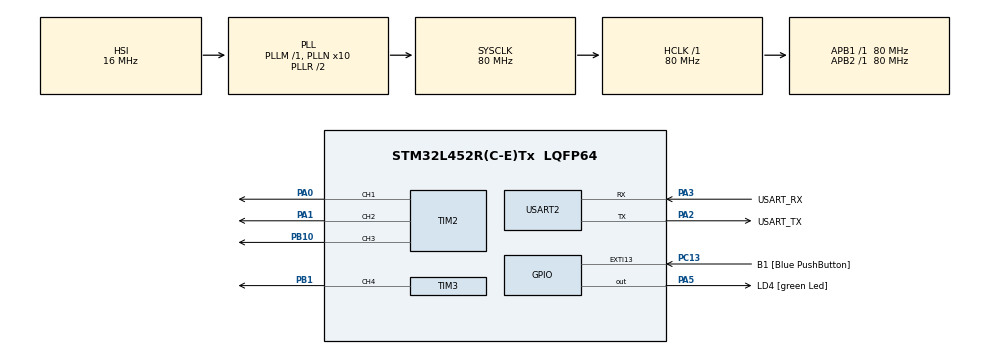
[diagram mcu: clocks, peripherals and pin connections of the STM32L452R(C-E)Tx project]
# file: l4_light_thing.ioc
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Mcu.Family=STM32L4
PA2.GPIO_PuPd=GPIO_NOPULL
RCC.CortexFreq_Value=80000000
PH0-OSC_IN\ (PH0).Signal=RCC_OSC_IN
Dma.TIM3_CH4/UP.0.Mode=DMA_NORMAL
PA3.GPIO_PuPd=GPIO_NOPULL
PA2.GPIO_Speed=GPIO_SPEED_FREQ_VERY_HIGH
PC15-OSC32_OUT\ (PC15).Mode=LSE-External-Oscillator
TIM2.Channel-PWM\ Generation2\ CH2=TIM_CHANNEL_2
PC13.GPIO_Label=B1 [Blue PushButton]
PA3.GPIO_Speed=GPIO_SPEED_FREQ_VERY_HIGH
TIM3.Channel-PWM\ Generation4\ CH4=TIM_CHANNEL_4
RCC.SYSCLKSource=RCC_SYSCLKSOURCE_PLLCLK
ProjectManager.StackSize=0x400
PC14-OSC32_IN\ (PC14).Mode=LSE-External-Oscillator
NVIC.DMA1_Channel3_IRQn=true\:0\:0\:false\:false\:true\:false\:true
PA14\ (JTCK/SWCLK).Signal=SYS_JTCK-SWCLK
RCC.HCLKFreq_Value=80000000
RCC.APB2TimFreq_Value=80000000
RCC.AHBFreq_Value=80000000
RCC.PREFETCH_ENABLE=1
RCC.HSE_VALUE=8000000
USART2.VirtualMode-Asynchronous=VM_ASYNC
PA13\ (JTMS/SWDIO).GPIO_Label=TMS
PB1.GPIO_Speed=GPIO_SPEED_FREQ_VERY_HIGH
PA5.GPIO_PuPd=GPIO_NOPULL
PC13.GPIO_PuPd=GPIO_NOPULL
PA14\ (JTCK/SWCLK).Mode=Serial_Wire
TIM2.Channel-PWM\ Generation1\ CH1=TIM_CHANNEL_1
PA0.Signal=S_TIM2_CH1
Mcu.Package=LQFP64
PB1.Signal=S_TIM3_CH4
Dma.TIM3_CH4/UP.0.Priority=DMA_PRIORITY_LOW
PA2.GPIO_Label=USART_TX
Dma.TIM3_CH4/UP.0.Direction=DMA_MEMORY_TO_PERIPH
PA14\ (JTCK/SWCLK).GPIO_Label=TCK
RCC.APB1TimFreq_Value=80000000
Dma.Request0=TIM3_CH4/UP
Dma.TIM3_CH4/UP.0.PeriphDataAlignment=DMA_PDATAALIGN_WORD
VP_TIM3_VS_ClockSourceINT.Mode=Internal
RCC.HSI48_VALUE=48000000
PA3.Signal=USART2_RX
PA2.GPIO_Mode=GPIO_MODE_AF_PP
PB3\ (JTDO/TRACESWO).GPIO_Label=SWO
RCC.MSI_VALUE=4000000
RCC.PLLSourceVirtual=RCC_PLLSOURCE_HSI
SH.S_TIM2_CH1.0=TIM2_CH1,PWM Generation1 CH1
PA13\ (JTMS/SWDIO).Mode=Serial_Wire
TIM3.AutoReloadPreload=TIM_AUTORELOAD_PRELOAD_ENABLE
PC13.Signal=GPXTI13
PC15-OSC32_OUT\ (PC15).Signal=RCC_OSC32_OUT
PH1-OSC_OUT\ (PH1).Signal=RCC_OSC_OUT
PA3.Mode=Asynchronous
SH.S_TIM2_CH2.0=TIM2_CH2,PWM Generation2 CH2
PB3\ (JTDO/TRACESWO).Signal=SYS_JTDO-SWO
ProjectManager.TargetToolchain=Makefile
PA3.GPIO_Mode=GPIO_MODE_AF_PP
Dma.TIM3_CH4/UP.0.Instance=DMA1_Channel3
RCC.USBFreq_Value=64000000
PA1.Signal=S_TIM2_CH2
PB10.Signal=S_TIM2_CH3
PA5.Signal=GPIO_Output
board=NUCLEO-L452RE
RCC.VCOOutputFreq_Value=160000000
RCC.APB2Freq_Value=80000000
PA5.GPIO_ModeDefaultOutputPP=GPIO_MODE_OUTPUT_PP
SH.S_TIM2_CH3.0=TIM2_CH3,PWM Generation3 CH3
RCC.ADCFreq_Value=64000000
TIM2.Channel-PWM\ Generation3\ CH3=TIM_CHANNEL_3
Dma.TIM3_CH4/UP.0.MemInc=DMA_MINC_ENABLE
Mcu.Name=STM32L452R(C-E)Tx
PA2.Signal=USART2_TX
RCC.SYSCLKFreq_VALUE=80000000
PA5.GPIO_Label=LD4 [green Led]
PC13.GPIO_ModeDefaultEXTI=GPIO_MODE_IT_FALLING
PC14-OSC32_IN\ (PC14).Signal=RCC_OSC32_IN
ProjectManager.HeapSize=0x200
Dma.TIM3_CH4/UP.0.MemDataAlignment=DMA_MDATAALIGN_BYTE
RCC.HSI_VALUE=16000000
PA5.GPIO_Speed=GPIO_SPEED_FREQ_LOW
NVIC.PriorityGroup=NVIC_PRIORITYGROUP_4
RCC.PLLN=10
PA2.Mode=Asynchronous
RCC.APB1Freq_Value=80000000
Dma.TIM3_CH4/UP.0.PeriphInc=DMA_PINC_DISABLE
PA13\ (JTMS/SWDIO).Signal=SYS_JTMS-SWDIO
PA3.GPIO_Label=USART_RX
SH.S_TIM3_CH4.0=TIM3_CH4,PWM Generation4 CH4

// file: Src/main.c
/* USER CODE BEGIN Header */
/**
  ******************************************************************************
  * @file           : main.c
  * @brief          : Main program body
  ******************************************************************************
  * @attention
  *
  * <h2><center>&copy; Copyright (c) 2020 STMicroelectronics.
  * All rights reserved.</center></h2>
  *
  * This software component is licensed by ST under BSD 3-Clause license,
  * the "License"; You may not use this file except in compliance with the
  * License. You may obtain a copy of the License at:
  *                        opensource.org/licenses/BSD-3-Clause
  *
  ******************************************************************************
  */
/* USER CODE END Header */

#include "main.h"
#include "dma.h"
#include "tim.h"
#include "usart.h"
#include "gpio.h"

/* USER CODE BEGIN Includes */
#include "addressable_led_driver.h"
/* USER CODE END Includes */

void SystemClock_Config(void);

int main(void)
{

  /* MCU Configuration--------------------------------------------------------*/

  /* Reset of all peripherals, Initializes the Flash interface and the Systick. */
  HAL_Init();

  /* Configure the system clock */
  SystemClock_Config();

  /* Initialize all configured peripherals */
  MX_GPIO_Init();
  MX_DMA_Init();
  MX_TIM2_Init();
  MX_TIM3_Init();
  MX_USART2_UART_Init();
  /* USER CODE BEGIN 2 */
  AddrLED_Init();
  /* USER CODE END 2 */

  /* Infinite loop */
  while (1)
  {

  }
}

void SystemClock_Config(void)
{
  RCC_OscInitTypeDef RCC_OscInitStruct = {0};
  RCC_ClkInitTypeDef RCC_ClkInitStruct = {0};
  RCC_PeriphCLKInitTypeDef PeriphClkInit = {0};

  /** Initializes the CPU, AHB and APB busses clocks
  */
  RCC_OscInitStruct.OscillatorType = RCC_OSCILLATORTYPE_HSI;
  RCC_OscInitStruct.HSIState = RCC_HSI_ON;
  RCC_OscInitStruct.HSICalibrationValue = RCC_HSICALIBRATION_DEFAULT;
  RCC_OscInitStruct.PLL.PLLState = RCC_PLL_ON;
  RCC_OscInitStruct.PLL.PLLSource = RCC_PLLSOURCE_HSI;
  RCC_OscInitStruct.PLL.PLLM = 1;
  RCC_OscInitStruct.PLL.PLLN = 10;
  RCC_OscInitStruct.PLL.PLLP = RCC_PLLP_DIV7;
  RCC_OscInitStruct.PLL.PLLQ = RCC_PLLQ_DIV2;
  RCC_OscInitStruct.PLL.PLLR = RCC_PLLR_DIV2;
  if (HAL_RCC_OscConfig(&RCC_OscInitStruct) != HAL_OK)
  {
    Error_Handler();
  }
  /** Initializes the CPU, AHB and APB busses clocks
  */
  RCC_ClkInitStruct.ClockType = RCC_CLOCKTYPE_HCLK|RCC_CLOCKTYPE_SYSCLK
                              |RCC_CLOCKTYPE_PCLK1|RCC_CLOCKTYPE_PCLK2;
  RCC_ClkInitStruct.SYSCLKSource = RCC_SYSCLKSOURCE_PLLCLK;
  RCC_ClkInitStruct.AHBCLKDivider = RCC_SYSCLK_DIV1;
  RCC_ClkInitStruct.APB1CLKDivider = RCC_HCLK_DIV1;
  RCC_ClkInitStruct.APB2CLKDivider = RCC_HCLK_DIV1;

  if (HAL_RCC_ClockConfig(&RCC_ClkInitStruct, FLASH_LATENCY_4) != HAL_OK)
  {
    Error_Handler();
  }
  PeriphClkInit.PeriphClockSelection = RCC_PERIPHCLK_USART2;
  PeriphClkInit.Usart2ClockSelection = RCC_USART2CLKSOURCE_PCLK1;
  if (HAL_RCCEx_PeriphCLKConfig(&PeriphClkInit) != HAL_OK)
  {
    Error_Handler();
  }
  /** Configure the main internal regulator output voltage
  */
  if (HAL_PWREx_ControlVoltageScaling(PWR_REGULATOR_VOLTAGE_SCALE1) != HAL_OK)
  {
    Error_Handler();
  }
}

void Error_Handler(void)
{
}

/************************ (C) COPYRIGHT STMicroelectronics *****END OF FILE****/
